# SGX_CM register map
Vendor: Texas Instruments
Peripheral module from a debugger description file (folder omap36xx).
Registers are 32-bit, access per field, reset 0x0 unless marked. A register's access mark holds for its fields unless they carry their own. Offsets are as the file gives them; lines under a group give offsets from that group; [hi:lo] are bit positions; {n}, {i} and the like mark numbered series; 'fields as' and 'values as' point back to an identical list; <NAME> marks a mode.

## SGX_CM
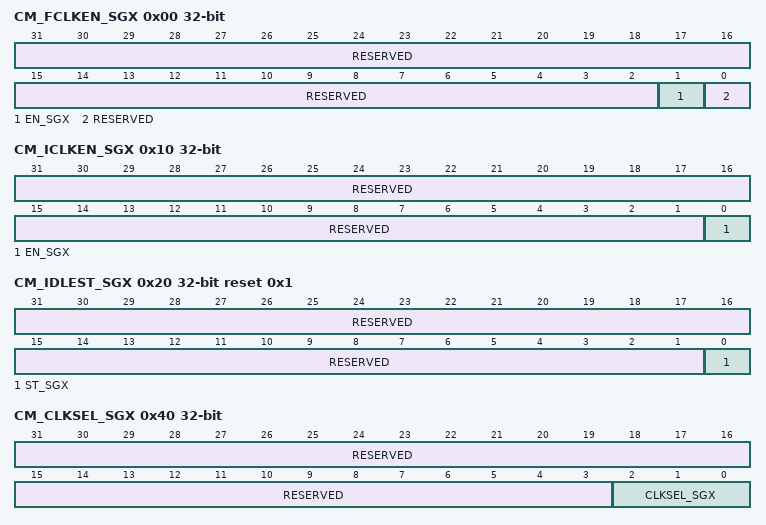
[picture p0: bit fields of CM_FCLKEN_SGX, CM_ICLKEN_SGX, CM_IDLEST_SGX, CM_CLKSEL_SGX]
0x00 CM_FCLKEN_SGX — Controls the Graphic engine functional clock activity.
  [31:2] RESERVED ro — Write 0s for future compatibility. Read returns 0.
  [1] EN_SGX rw — SGX functional clock enable
    0=SGX_FCLK is disabled; 1=SGX_FCLK is enabled
  [0] RESERVED ro — Write 0s for future compatibility. Read returns 0.
0x10 CM_ICLKEN_SGX — Controls the Graphic engine interface clock activity.
  [31:1] RESERVED ro — Write 0s for future compatibility. Read returns 0.
  [0] EN_SGX rw — SGX interface clock control
    0=SGX_L3_ICLK is disabled; 1=SGX_L3_ICLK is enabled
0x20 CM_IDLEST_SGX ro reset 0x1 — SGX standby status. This register is read only and automatically updated.
  [31:1] RESERVED — Read returns 0
  [0] ST_SGX — SGX standby status.
    0=SGX subsystem is active; 1=SGX subsystem is in standby mode
0x40 CM_CLKSEL_SGX — SGX clock selection.
  [31:3] RESERVED ro — Write 0s for future compatibility. Read return 0.
  [2:0] CLKSEL_SGX rw — Selects SGX functional clock
    0=SGX functional clock is CORE_CLK divided by 3; 1=SGX functional clock is CORE_CLK divided by 4; 2=SGX functional clock is CORE_CLK divided by 6; 3=SGX functional clock is CM_96M_FCLK clock; 4=SGX functional clock is SGX_192M_FCLK clock; 5=SGX functional clock is CORE_CLK divided by 2; 6=SGX functional clock is COREX2_CLK divided by 3; 7=SGX functional clock is COREX2_CLK divided by 5
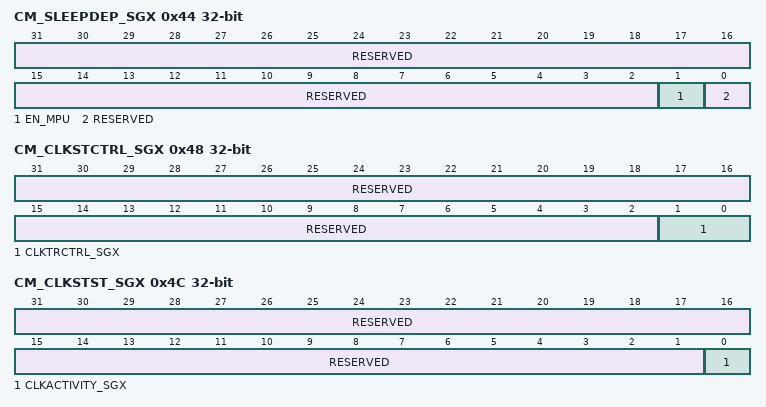
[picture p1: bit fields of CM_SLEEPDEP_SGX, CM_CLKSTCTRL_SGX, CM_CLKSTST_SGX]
0x44 CM_SLEEPDEP_SGX — This register allows enabling or disabling the sleep transition dependency of SGX domain with respect to other domain.
  [31:2] RESERVED ro — Write 0s for future compatibility. Read returns 0.
  [1] EN_MPU rw — MPU domain dependency
    0=SGX domain sleep dependency with MPU domain is disabled; 1=SGX domain sleep dependency with MPU domain is enabled
  [0] RESERVED ro — Write 0s for future compatibility. Read returns 0.
0x48 CM_CLKSTCTRL_SGX — This register enables the domain power state transition. It controls the HW supervised domain power state transition between ACTIVE and INACTIVE states.
  [31:2] RESERVED ro — Write 0s for future compatibility. Reads returns 0.
  [1:0] CLKTRCTRL_SGX rw — Controls the clock state transition of the SGX clock domain.
    0=Automatic transition is disabled; 1=Start a software supervised sleep transition on the domain; 2=Start a software supervised wake-up transition on the domain; 3=Automatic transition is enabled. Transition is supervised by the hardware.
0x4C CM_CLKSTST_SGX ro — This register provides a status on the interface clock activity in the domain.
  [31:1] RESERVED — Write 0s for future compatibility. Read returns 0.
  [0] CLKACTIVITY_SGX — Interface clock activity status
    0=No domain interface clock activity; 1=Domain interface clock is active
